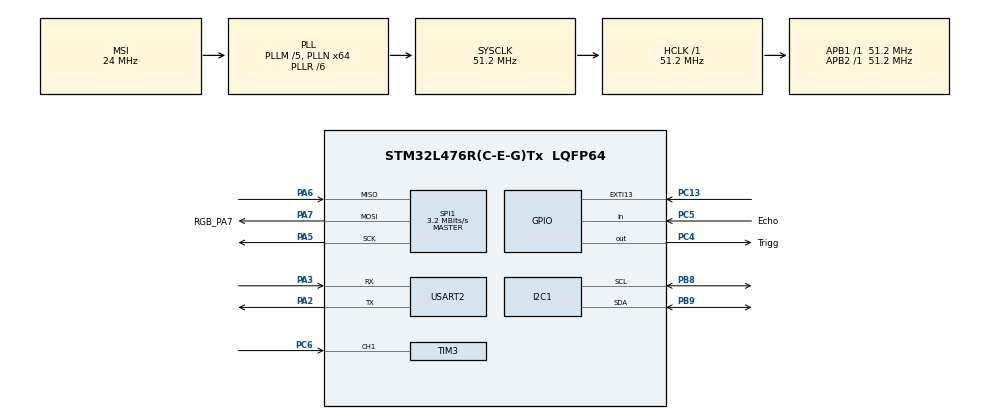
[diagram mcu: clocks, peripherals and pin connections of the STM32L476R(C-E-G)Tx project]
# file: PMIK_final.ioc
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I2C1.Timing=0x00C0F7FE
Mcu.Family=STM32L4
Mcu.Name=STM32L476R(C-E-G)Tx
Mcu.Package=LQFP64
NVIC.EXTI15_10_IRQn=true\:2\:0\:true\:false\:true\:true\:true
NVIC.PriorityGroup=NVIC_PRIORITYGROUP_4
NVIC.TIM2_IRQn=true\:2\:0\:true\:false\:true\:true\:true
NVIC.TIM3_IRQn=true\:1\:0\:true\:false\:true\:true\:true
NVIC.USART2_IRQn=true\:3\:0\:true\:false\:true\:true\:true
PA13\ (JTMS-SWDIO).Mode=Serial_Wire
PA13\ (JTMS-SWDIO).Signal=SYS_JTMS-SWDIO
PA14\ (JTCK-SWCLK).Mode=Serial_Wire
PA14\ (JTCK-SWCLK).Signal=SYS_JTCK-SWCLK
PA2.GPIO_Mode=GPIO_MODE_AF_PP
PA2.GPIO_ModeDefaultPP=GPIO_MODE_AF_PP
PA2.GPIO_PuPd=GPIO_NOPULL
PA2.GPIO_Speed=GPIO_SPEED_FREQ_VERY_HIGH
PA2.Mode=Asynchronous
PA2.Signal=USART2_TX
PA3.GPIO_Mode=GPIO_MODE_AF_PP
PA3.GPIO_ModeDefaultPP=GPIO_MODE_AF_OD
PA3.GPIO_PuPd=GPIO_NOPULL
PA3.GPIO_Speed=GPIO_SPEED_FREQ_VERY_HIGH
PA3.Mode=Asynchronous
PA3.Signal=USART2_RX
PA5.Mode=Full_Duplex_Master
PA5.Signal=SPI1_SCK
PA6.Mode=Full_Duplex_Master
PA6.Signal=SPI1_MISO
PA7.GPIO_Label=RGB_PA7
PA7.Mode=Full_Duplex_Master
PA7.Signal=SPI1_MOSI
PB3\ (JTDO-TRACESWO).Signal=SYS_JTDO-SWO
PB8.Mode=I2C
PB8.Signal=I2C1_SCL
PB9.Mode=I2C
PB9.Signal=I2C1_SDA
PC13.GPIO_ModeDefaultEXTI=GPIO_MODE_IT_RISING
PC13.GPIO_PuPd=GPIO_NOPULL
PC13.Signal=GPXTI13
PC14-OSC32_IN\ (PC14).Mode=LSE-External-Oscillator
PC14-OSC32_IN\ (PC14).Signal=RCC_OSC32_IN
PC15-OSC32_OUT\ (PC15).Mode=LSE-External-Oscillator
PC15-OSC32_OUT\ (PC15).Signal=RCC_OSC32_OUT
PC4.GPIO_Label=Trigg
PC4.GPIO_Speed=GPIO_SPEED_FREQ_HIGH
PC4.PinState=GPIO_PIN_SET
PC4.Signal=GPIO_Output
PC5.GPIO_Label=Echo
PC5.Signal=GPIO_Input
PC6.Signal=S_TIM3_CH1
PH0-OSC_IN\ (PH0).Signal=RCC_OSC_IN
PH1-OSC_OUT\ (PH1).Signal=RCC_OSC_OUT
ProjectManager.HeapSize=0x200
ProjectManager.StackSize=0x400
ProjectManager.TargetToolchain=STM32CubeIDE
RCC.ADCFreq_Value=19200000
RCC.AHBFreq_Value=51200000
RCC.APB1Freq_Value=51200000
RCC.APB1TimFreq_Value=51200000
RCC.APB2Freq_Value=51200000
RCC.APB2TimFreq_Value=51200000
RCC.CortexFreq_Value=51200000
RCC.HCLKFreq_Value=51200000
RCC.HSE_VALUE=8000000
RCC.HSI_VALUE=16000000
RCC.MSIClockRange=RCC_MSIRANGE_9
RCC.MSI_VALUE=24000000
RCC.PLLM=5
RCC.PLLN=64
RCC.PLLR=RCC_PLLR_DIV6
RCC.PREFETCH_ENABLE=1
RCC.SYSCLKFreq_VALUE=51200000
RCC.SYSCLKSource=RCC_SYSCLKSOURCE_PLLCLK
RCC.USBFreq_Value=19200000
RCC.VCOOutputFreq_Value=307200000
SH.S_TIM3_CH1.0=TIM3_CH1,Input_Capture1_from_TI1
SPI1.BaudRatePrescaler=SPI_BAUDRATEPRESCALER_16
SPI1.CalculateBaudRate=3.2 MBits/s
SPI1.DataSize=SPI_DATASIZE_4BIT
SPI1.Direction=SPI_DIRECTION_2LINES
SPI1.FirstBit=SPI_FIRSTBIT_MSB
SPI1.Mode=SPI_MODE_MASTER
SPI1.VirtualType=VM_MASTER
TIM2.Channel-Output\ Compare1\ No\ Output=TIM_CHANNEL_1
TIM2.ClockDivision=TIM_CLOCKDIVISION_DIV1
TIM2.Period=511
TIM2.Prescaler=3999
TIM3.Channel-Input_Capture1_from_TI1=TIM_CHANNEL_1
TIM3.ClockDivision=TIM_CLOCKDIVISION_DIV1
TIM3.Period=600
TIM3.Prescaler=0
USART2.VirtualMode-Asynchronous=VM_ASYNC
VP_TIM2_VS_no_output1.Mode=Output Compare1 No Output
board=NUCLEO-L476RG

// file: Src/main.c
/* USER CODE BEGIN Header */
/**
 ******************************************************************************
 * @file           : main.c
 * @brief          : Main program body
 ******************************************************************************
 * @attention
 *
 * <h2><center>&copy; Copyright (c) 2019 STMicroelectronics.
 * All rights reserved.</center></h2>
 *
 * This software component is licensed by ST under BSD 3-Clause license,
 * the "License"; You may not use this file except in compliance with the
 * License. You may obtain a copy of the License at:
 *                        opensource.org/licenses/BSD-3-Clause
 *
 ******************************************************************************
 */
/* USER CODE END Header */

#include "main.h"

I2C_HandleTypeDef hi2c1;

SPI_HandleTypeDef hspi1;

TIM_HandleTypeDef htim2;
TIM_HandleTypeDef htim3;

UART_HandleTypeDef huart2;

void SystemClock_Config(void);
static void MX_GPIO_Init(void);
static void MX_USART2_UART_Init(void);
static void MX_TIM3_Init(void);
static void MX_SPI1_Init(void);
static void MX_I2C1_Init(void);
static void MX_TIM2_Init(void);

int main(void)
{

  /* MCU Configuration--------------------------------------------------------*/

  /* Reset of all peripherals, Initializes the Flash interface and the Systick. */
  HAL_Init();

  /* Configure the system clock */
  SystemClock_Config();

  /* Initialize all configured peripherals */
  MX_GPIO_Init();
  MX_USART2_UART_Init();
  MX_TIM3_Init();
  MX_SPI1_Init();
  MX_I2C1_Init();
  MX_TIM2_Init();
  /* USER CODE BEGIN 2 */
	// Initialize created libraries
	initializeLEDs(&hspi1, 0, 1, 0);
	init_hcsr();
	APDS_init(&hi2c1);
	HAL_Delay(200);
	// Start needed modules - timers and UART
	HAL_TIM_Base_Start_IT(&htim2);
	initUart(&huart2);
	HAL_TIM_Base_Start_IT(&htim3);
	// Start communication with computer
	startProgram();
  /* USER CODE END 2 */

  /* Infinite loop */
	while (1) {

    /* USER CODE BEGIN 3 */
		//	HAL_Delay(1000); /* Insert delay 100 ms */
	}
  /* USER CODE END 3 */
}

void SystemClock_Config(void)
{
  RCC_OscInitTypeDef RCC_OscInitStruct = {0};
  RCC_ClkInitTypeDef RCC_ClkInitStruct = {0};
  RCC_PeriphCLKInitTypeDef PeriphClkInit = {0};

  /** Configure LSE Drive Capability
  */
  HAL_PWR_EnableBkUpAccess();
  __HAL_RCC_LSEDRIVE_CONFIG(RCC_LSEDRIVE_LOW);
  /** Initializes the CPU, AHB and APB busses clocks
  */
  RCC_OscInitStruct.OscillatorType = RCC_OSCILLATORTYPE_LSE|RCC_OSCILLATORTYPE_MSI;
  RCC_OscInitStruct.LSEState = RCC_LSE_ON;
  RCC_OscInitStruct.MSIState = RCC_MSI_ON;
  RCC_OscInitStruct.MSICalibrationValue = 0;
  RCC_OscInitStruct.MSIClockRange = RCC_MSIRANGE_9;
  RCC_OscInitStruct.PLL.PLLState = RCC_PLL_ON;
  RCC_OscInitStruct.PLL.PLLSource = RCC_PLLSOURCE_MSI;
  RCC_OscInitStruct.PLL.PLLM = 5;
  RCC_OscInitStruct.PLL.PLLN = 64;
  RCC_OscInitStruct.PLL.PLLP = RCC_PLLP_DIV7;
  RCC_OscInitStruct.PLL.PLLQ = RCC_PLLQ_DIV2;
  RCC_OscInitStruct.PLL.PLLR = RCC_PLLR_DIV6;
  if (HAL_RCC_OscConfig(&RCC_OscInitStruct) != HAL_OK)
  {
    Error_Handler();
  }
  /** Initializes the CPU, AHB and APB busses clocks
  */
  RCC_ClkInitStruct.ClockType = RCC_CLOCKTYPE_HCLK|RCC_CLOCKTYPE_SYSCLK
                              |RCC_CLOCKTYPE_PCLK1|RCC_CLOCKTYPE_PCLK2;
  RCC_ClkInitStruct.SYSCLKSource = RCC_SYSCLKSOURCE_PLLCLK;
  RCC_ClkInitStruct.AHBCLKDivider = RCC_SYSCLK_DIV1;
  RCC_ClkInitStruct.APB1CLKDivider = RCC_HCLK_DIV1;
  RCC_ClkInitStruct.APB2CLKDivider = RCC_HCLK_DIV1;

  if (HAL_RCC_ClockConfig(&RCC_ClkInitStruct, FLASH_LATENCY_3) != HAL_OK)
  {
    Error_Handler();
  }
  PeriphClkInit.PeriphClockSelection = RCC_PERIPHCLK_USART2|RCC_PERIPHCLK_I2C1;
  PeriphClkInit.Usart2ClockSelection = RCC_USART2CLKSOURCE_PCLK1;
  PeriphClkInit.I2c1ClockSelection = RCC_I2C1CLKSOURCE_PCLK1;
  if (HAL_RCCEx_PeriphCLKConfig(&PeriphClkInit) != HAL_OK)
  {
    Error_Handler();
  }
  /** Configure the main internal regulator output voltage
  */
  if (HAL_PWREx_ControlVoltageScaling(PWR_REGULATOR_VOLTAGE_SCALE1) != HAL_OK)
  {
    Error_Handler();
  }
  /** Enable MSI Auto calibration
  */
  HAL_RCCEx_EnableMSIPLLMode();
}

static void MX_I2C1_Init(void)
{

  hi2c1.Instance = I2C1;
  hi2c1.Init.Timing = 0x00C0F7FE;
  hi2c1.Init.OwnAddress1 = 0;
  hi2c1.Init.AddressingMode = I2C_ADDRESSINGMODE_7BIT;
  hi2c1.Init.DualAddressMode = I2C_DUALADDRESS_DISABLE;
  hi2c1.Init.OwnAddress2 = 0;
  hi2c1.Init.OwnAddress2Masks = I2C_OA2_NOMASK;
  hi2c1.Init.GeneralCallMode = I2C_GENERALCALL_DISABLE;
  hi2c1.Init.NoStretchMode = I2C_NOSTRETCH_DISABLE;
  if (HAL_I2C_Init(&hi2c1) != HAL_OK)
  {
    Error_Handler();
  }
  /** Configure Analogue filter
  */
  if (HAL_I2CEx_ConfigAnalogFilter(&hi2c1, I2C_ANALOGFILTER_ENABLE) != HAL_OK)
  {
    Error_Handler();
  }
  /** Configure Digital filter
  */
  if (HAL_I2CEx_ConfigDigitalFilter(&hi2c1, 0) != HAL_OK)
  {
    Error_Handler();
  }

}

static void MX_SPI1_Init(void)
{

  /* SPI1 parameter configuration*/
  hspi1.Instance = SPI1;
  hspi1.Init.Mode = SPI_MODE_MASTER;
  hspi1.Init.Direction = SPI_DIRECTION_2LINES;
  hspi1.Init.DataSize = SPI_DATASIZE_4BIT;
  hspi1.Init.CLKPolarity = SPI_POLARITY_LOW;
  hspi1.Init.CLKPhase = SPI_PHASE_1EDGE;
  hspi1.Init.NSS = SPI_NSS_SOFT;
  hspi1.Init.BaudRatePrescaler = SPI_BAUDRATEPRESCALER_16;
  hspi1.Init.FirstBit = SPI_FIRSTBIT_MSB;
  hspi1.Init.TIMode = SPI_TIMODE_DISABLE;
  hspi1.Init.CRCCalculation = SPI_CRCCALCULATION_DISABLE;
  hspi1.Init.CRCPolynomial = 7;
  hspi1.Init.CRCLength = SPI_CRC_LENGTH_DATASIZE;
  hspi1.Init.NSSPMode = SPI_NSS_PULSE_ENABLE;
  if (HAL_SPI_Init(&hspi1) != HAL_OK)
  {
    Error_Handler();
  }

}

static void MX_TIM2_Init(void)
{

  TIM_MasterConfigTypeDef sMasterConfig = {0};
  TIM_OC_InitTypeDef sConfigOC = {0};

  htim2.Instance = TIM2;
  htim2.Init.Prescaler = 3999;
  htim2.Init.CounterMode = TIM_COUNTERMODE_UP;
  htim2.Init.Period = 511;
  htim2.Init.ClockDivision = TIM_CLOCKDIVISION_DIV1;
  htim2.Init.AutoReloadPreload = TIM_AUTORELOAD_PRELOAD_DISABLE;
  if (HAL_TIM_OC_Init(&htim2) != HAL_OK)
  {
    Error_Handler();
  }
  sMasterConfig.MasterOutputTrigger = TIM_TRGO_RESET;
  sMasterConfig.MasterSlaveMode = TIM_MASTERSLAVEMODE_DISABLE;
  if (HAL_TIMEx_MasterConfigSynchronization(&htim2, &sMasterConfig) != HAL_OK)
  {
    Error_Handler();
  }
  sConfigOC.OCMode = TIM_OCMODE_TIMING;
  sConfigOC.Pulse = 0;
  sConfigOC.OCPolarity = TIM_OCPOLARITY_HIGH;
  sConfigOC.OCFastMode = TIM_OCFAST_DISABLE;
  if (HAL_TIM_OC_ConfigChannel(&htim2, &sConfigOC, TIM_CHANNEL_1) != HAL_OK)
  {
    Error_Handler();
  }

}

static void MX_TIM3_Init(void)
{

  TIM_MasterConfigTypeDef sMasterConfig = {0};
  TIM_IC_InitTypeDef sConfigIC = {0};

  htim3.Instance = TIM3;
  htim3.Init.Prescaler = 0;
  htim3.Init.CounterMode = TIM_COUNTERMODE_UP;
  htim3.Init.Period = 600;
  htim3.Init.ClockDivision = TIM_CLOCKDIVISION_DIV1;
  htim3.Init.AutoReloadPreload = TIM_AUTORELOAD_PRELOAD_DISABLE;
  if (HAL_TIM_IC_Init(&htim3) != HAL_OK)
  {
    Error_Handler();
  }
  sMasterConfig.MasterOutputTrigger = TIM_TRGO_RESET;
  sMasterConfig.MasterSlaveMode = TIM_MASTERSLAVEMODE_DISABLE;
  if (HAL_TIMEx_MasterConfigSynchronization(&htim3, &sMasterConfig) != HAL_OK)
  {
    Error_Handler();
  }
  sConfigIC.ICPolarity = TIM_INPUTCHANNELPOLARITY_RISING;
  sConfigIC.ICSelection = TIM_ICSELECTION_DIRECTTI;
  sConfigIC.ICPrescaler = TIM_ICPSC_DIV1;
  sConfigIC.ICFilter = 0;
  if (HAL_TIM_IC_ConfigChannel(&htim3, &sConfigIC, TIM_CHANNEL_1) != HAL_OK)
  {
    Error_Handler();
  }

}

static void MX_USART2_UART_Init(void)
{

  huart2.Instance = USART2;
  huart2.Init.BaudRate = 115200;
  huart2.Init.WordLength = UART_WORDLENGTH_8B;
  huart2.Init.StopBits = UART_STOPBITS_1;
  huart2.Init.Parity = UART_PARITY_NONE;
  huart2.Init.Mode = UART_MODE_TX_RX;
  huart2.Init.HwFlowCtl = UART_HWCONTROL_NONE;
  huart2.Init.OverSampling = UART_OVERSAMPLING_16;
  huart2.Init.OneBitSampling = UART_ONE_BIT_SAMPLE_DISABLE;
  huart2.AdvancedInit.AdvFeatureInit = UART_ADVFEATURE_NO_INIT;
  if (HAL_UART_Init(&huart2) != HAL_OK)
  {
    Error_Handler();
  }

}

static void MX_GPIO_Init(void)
{
  GPIO_InitTypeDef GPIO_InitStruct = {0};

  /* GPIO Ports Clock Enable */
  __HAL_RCC_GPIOC_CLK_ENABLE();
  __HAL_RCC_GPIOH_CLK_ENABLE();
  __HAL_RCC_GPIOA_CLK_ENABLE();
  __HAL_RCC_GPIOB_CLK_ENABLE();

  /*Configure GPIO pin Output Level */
  HAL_GPIO_WritePin(Trigg_GPIO_Port, Trigg_Pin, GPIO_PIN_SET);

  /*Configure GPIO pin : PC13 */
  GPIO_InitStruct.Pin = GPIO_PIN_13;
  GPIO_InitStruct.Mode = GPIO_MODE_IT_RISING;
  GPIO_InitStruct.Pull = GPIO_NOPULL;
  HAL_GPIO_Init(GPIOC, &GPIO_InitStruct);

  /*Configure GPIO pin : Trigg_Pin */
  GPIO_InitStruct.Pin = Trigg_Pin;
  GPIO_InitStruct.Mode = GPIO_MODE_OUTPUT_PP;
  GPIO_InitStruct.Pull = GPIO_NOPULL;
  GPIO_InitStruct.Speed = GPIO_SPEED_FREQ_HIGH;
  HAL_GPIO_Init(Trigg_GPIO_Port, &GPIO_InitStruct);

  /*Configure GPIO pin : Echo_Pin */
  GPIO_InitStruct.Pin = Echo_Pin;
  GPIO_InitStruct.Mode = GPIO_MODE_INPUT;
  GPIO_InitStruct.Pull = GPIO_NOPULL;
  HAL_GPIO_Init(Echo_GPIO_Port, &GPIO_InitStruct);

  /* EXTI interrupt init*/
  HAL_NVIC_SetPriority(EXTI15_10_IRQn, 2, 0);
  HAL_NVIC_EnableIRQ(EXTI15_10_IRQn);

}

/* USER CODE BEGIN 4 */
void calculate_illuminance(int mode) {
	uint16_t result = ALS_readCh0(&hi2c1);
	uint16_t result2 = ALS_readCh1(&hi2c1);
	float brightness = scale_results(result, result2);
	if (mode != IDLE)
		setIlluminance(brightness);
}
/* USER CODE END 4 */

void Error_Handler(void)
{
}

/************************ (C) COPYRIGHT STMicroelectronics *****END OF FILE****/
